# MCAN_MCAN_20700000h register map
Vendor: Texas Instruments
Peripheral module from a debugger description file (folder AM275x).
Registers are 32-bit, read-only, reset 0x0 unless marked. A register's access mark holds for its fields unless they carry their own. Offsets are as the file gives them; lines under a group give offsets from that group; [hi:lo] are bit positions; {n}, {i} and the like mark numbered series; 'fields as' and 'values as' point back to an identical list; <NAME> marks a mode.

## mcan
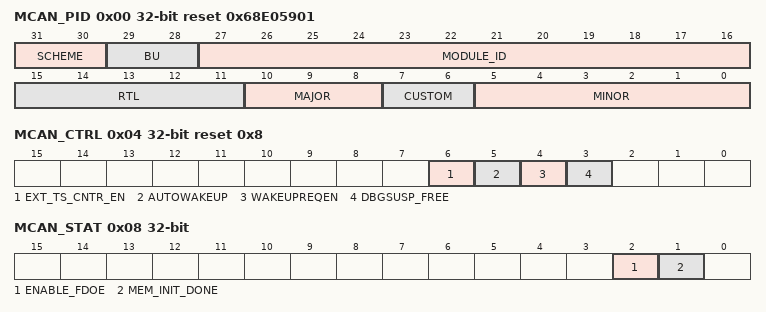
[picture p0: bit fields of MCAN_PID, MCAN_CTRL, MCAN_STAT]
0x00 MCAN_PID reset 0x68E05901 — The Revision Register contains the major and minor revisions for the module.
  [31:30] SCHEME — Scheme Reset Source: hsrst_n
  [29:28] BU — Business Unit 2h Processors
  [27:16] MODULE_ID — Module ID Reset Source: hsrst_n
  [15:11] RTL — RTL Revision Reset Source: hsrst_n
  [10:8] MAJOR — Major Revision Reset Source: hsrst_n
  [7:6] CUSTOM — Custom Reset Source: hsrst_n
  [5:0] MINOR — Minor Revision Reset Source: hsrst_n
0x04 MCAN_CTRL rw reset 0x8 — The Control Register contains general control bits for the MCANSS
  [6] EXT_TS_CNTR_EN — External Timestamp Counter Enable Reset Source: hsrst_n
  [5] AUTOWAKEUP — Automatic Wakeup Enable Reset Source: hsrst_n
  [4] WAKEUPREQEN — Wakeup Request Enable Reset Source: hsrst_n
  [3] DBGSUSP_FREE — Debug Suspend 0h Honor debug suspend1h Disregard debug suspend
0x08 MCAN_STAT — The Status register provide general status bits for the MCANSS
  [2] ENABLE_FDOE — Enable FD (Flexible Data-Rate) ConfigurationReflects the value of mcanss_enable_fdoe configuration port, xh mcanss_enable_fdoe.
  [1] MEM_INIT_DONE — Memory Initialization 0h Memory initialization is in progress1h Memory intialization done
0x0C MCAN_ICS wo — Write to clear interrupt bits
  [0] EXT_TS_CNTR_OVFL — External Timestamp Counter Overflow Interrupt Status Write 1h to clear bits. Reset Source: hsrst_n
0x10 MCAN_IRS access not given — Read raw interrupt status. Write '1' to set interrupt bits.
  [0] EXT_TS_CNTR_OVFL — External Timestamp Counter Overflow Interrupt Status Write 1h to set bits. Reset Source: hsrst_n (access R/W1TS)
0x14 MCAN_IECS access not given — Write to clear interrupt enable bits
  [0] EXT_TS_CNTR_OVFL — External Timestamp Counter Overflow Interrupt Write 1h to clear bits. Reset Source: hsrst_n (access W1TC)
0x18 MCAN_IE access not given — Read interrupt Enable
  [0] EXT_TS_CNTR_OVFL — External Timestamp Counter Overflow Interrupt Write 1h to set bits. Reset Source: hsrst_n (access R/W1TS)
0x1C MCAN_IES — Read Enabled Interrupts
  [0] EXT_TS_CNTR_OVFL — External Timestamp Counter Overflow Interrupt Reset Source: hsrst_n
0x20 MCAN_EOI wo — End of Interrupt Register
  [7:0] EOI — End Of Interrupt Write with bit position of the targeted interrupt (example: external timestamp is bit 0). Upon write, level interrupt will clear and if unserviced interrupt counter > 1h will issue another pulse interrupt. 0h EOI value for external timestamp interrupt1h EOI value for mcan[0] interrupt2h EOI value for mcan[1] interrupt
0x24 MCAN_EXT_TS_PRESCALER rw — External TImeStamp PreScaler
  [23:0] PRESCALER — External Timestamp Prescaler Reload Value External timestamp count rate is host clock rate divided by this value with one exception - a value of 0h has the same effect as 1h. Reset Source: hsrst_n
0x28 MCAN_EXT_TS_UNSERVICED_INTR_CNTR — External TImeStamp Unserviced Interrupts Counter
  [4:0] EXT_TS_INTR_CNTR — Number of Unserviced Rollover Interrupts If > 1h an EOI write will issue another pulse interrupt. Reset Source: hsrst_n
